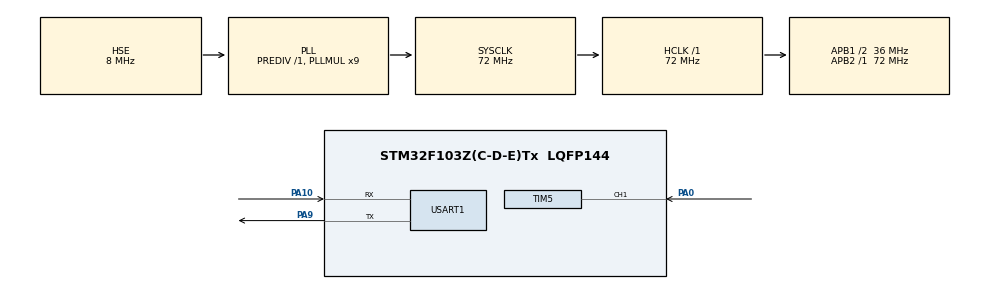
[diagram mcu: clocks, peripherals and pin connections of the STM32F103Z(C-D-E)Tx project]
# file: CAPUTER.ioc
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Mcu.Family=STM32F1
Mcu.Name=STM32F103Z(C-D-E)Tx
Mcu.Package=LQFP144
NVIC.PriorityGroup=NVIC_PRIORITYGROUP_4
NVIC.TIM5_IRQn=true\:0\:0\:false\:false\:true\:true\:true
OSC_IN.Mode=HSE-External-Oscillator
OSC_IN.Signal=RCC_OSC_IN
OSC_OUT.Mode=HSE-External-Oscillator
OSC_OUT.Signal=RCC_OSC_OUT
PA0-WKUP.GPIO_PuPd=GPIO_PULLDOWN
PA0-WKUP.Signal=S_TIM5_CH1
PA10.Mode=Asynchronous
PA10.Signal=USART1_RX
PA9.Mode=Asynchronous
PA9.Signal=USART1_TX
ProjectManager.HeapSize=0x200
ProjectManager.StackSize=0x400
ProjectManager.TargetToolchain=MDK-ARM V5
RCC.AHBFreq_Value=72000000
RCC.APB1CLKDivider=RCC_HCLK_DIV2
RCC.APB1Freq_Value=36000000
RCC.APB1TimFreq_Value=72000000
RCC.APB2Freq_Value=72000000
RCC.APB2TimFreq_Value=72000000
RCC.HCLKFreq_Value=72000000
RCC.PLLMUL=RCC_PLL_MUL9
RCC.PLLSourceVirtual=RCC_PLLSOURCE_HSE
RCC.SYSCLKFreq_VALUE=72000000
RCC.SYSCLKSource=RCC_SYSCLKSOURCE_PLLCLK
RCC.USBFreq_Value=72000000
SH.S_TIM5_CH1.0=TIM5_CH1,Input_Capture1_from_TI1
TIM5.AutoReloadPreload=TIM_AUTORELOAD_PRELOAD_ENABLE
TIM5.Channel-Input_Capture1_from_TI1=TIM_CHANNEL_1
TIM5.Period=0xFFFF
TIM5.Prescaler=72-1
USART1.VirtualMode=VM_ASYNC
VP_SYS_VS_ND.Mode=No_Debug
VP_TIM5_VS_ClockSourceINT.Mode=Internal
board=custom

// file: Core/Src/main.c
/* USER CODE BEGIN Header */
/**
  ******************************************************************************
  * @file           : main.c
  * @brief          : Main program body
  ******************************************************************************
  * @attention
  *
  * <h2><center>&copy; Copyright (c) 2021 STMicroelectronics.
  * All rights reserved.</center></h2>
  *
  * This software component is licensed by ST under BSD 3-Clause license,
  * the "License"; You may not use this file except in compliance with the
  * License. You may obtain a copy of the License at:
  *                        opensource.org/licenses/BSD-3-Clause
  *
  ******************************************************************************
  */
/* USER CODE END Header */
#include "main.h"
#include "tim.h"
#include "usart.h"
#include "gpio.h"

/* USER CODE BEGIN Includes */
#include "stdio.h"
/* USER CODE END Includes */

void SystemClock_Config(void);

int main(void)
{

  /* MCU Configuration--------------------------------------------------------*/

  /* Reset of all peripherals, Initializes the Flash interface and the Systick. */
  HAL_Init();

  /* Configure the system clock */
  SystemClock_Config();

  /* Initialize all configured peripherals */
  MX_GPIO_Init();
  MX_TIM5_Init();
  MX_USART1_UART_Init();

  /* Infinite loop */
  while (1)
  {

    /* USER CODE BEGIN 3 */
      switch (TIM5_CAPTURE_STA)
    {
        case 0:
        {
            printf("# start ----------------------------------------------------\r\n");
            printf("准备捕获上升沿...\r\n");
            TIM5_TIMEOUT_COUNT = 0;
            __HAL_TIM_SET_COUNTER(&htim5, 0);											// 清除定时器2现有计数
            TIM5_CAPTURE_BUF[0] = 0;                                                    // 清除捕获计数
            TIM5_CAPTURE_BUF[1] = 0;
            TIM5_CAPTURE_BUF[2] = 0;
            TIM5_SetCapturePolarity(TIM_INPUTCHANNELPOLARITY_RISING);					// 设置为上升沿触发
            HAL_TIM_Base_Start_IT(&htim5);												// 启动定时器更新中断
            HAL_TIM_IC_Start_IT(&htim5, TIM_CHANNEL_1);									// 启动捕获中断
            TIM5_CAPTURE_STA++;
            break;
        }

        case 4:
        {
            uint32_t high  = TIM5_CAPTURE_BUF[1] - TIM5_CAPTURE_BUF[0];
            uint32_t cycle = TIM5_CAPTURE_BUF[2] - TIM5_CAPTURE_BUF[0];
            float frq = 1.0 / (((float)cycle) / 1000000.0);
            TIM5_CAPTURE_STA = 0;

            printf("\r\n\r\n");
            printf("################################# START #########################################\r\n");
            printf("高电平持续时间：%dms\r\n", high / 1000);
            printf("周期          ：%dms\r\n", cycle / 1000);
            printf("频率          ：%fHz\r\n", frq);
            printf("################################## END ##########################################\r\n\r\n");
            break;
        }

        default:
            break;
    }
  }
  /* USER CODE END 3 */
}

void SystemClock_Config(void)
{
  RCC_OscInitTypeDef RCC_OscInitStruct = {0};
  RCC_ClkInitTypeDef RCC_ClkInitStruct = {0};

  /** Initializes the RCC Oscillators according to the specified parameters
  * in the RCC_OscInitTypeDef structure.
  */
  RCC_OscInitStruct.OscillatorType = RCC_OSCILLATORTYPE_HSE;
  RCC_OscInitStruct.HSEState = RCC_HSE_ON;
  RCC_OscInitStruct.HSEPredivValue = RCC_HSE_PREDIV_DIV1;
  RCC_OscInitStruct.HSIState = RCC_HSI_ON;
  RCC_OscInitStruct.PLL.PLLState = RCC_PLL_ON;
  RCC_OscInitStruct.PLL.PLLSource = RCC_PLLSOURCE_HSE;
  RCC_OscInitStruct.PLL.PLLMUL = RCC_PLL_MUL9;
  if (HAL_RCC_OscConfig(&RCC_OscInitStruct) != HAL_OK)
  {
    Error_Handler();
  }
  /** Initializes the CPU, AHB and APB buses clocks
  */
  RCC_ClkInitStruct.ClockType = RCC_CLOCKTYPE_HCLK|RCC_CLOCKTYPE_SYSCLK
                              |RCC_CLOCKTYPE_PCLK1|RCC_CLOCKTYPE_PCLK2;
  RCC_ClkInitStruct.SYSCLKSource = RCC_SYSCLKSOURCE_PLLCLK;
  RCC_ClkInitStruct.AHBCLKDivider = RCC_SYSCLK_DIV1;
  RCC_ClkInitStruct.APB1CLKDivider = RCC_HCLK_DIV2;
  RCC_ClkInitStruct.APB2CLKDivider = RCC_HCLK_DIV1;

  if (HAL_RCC_ClockConfig(&RCC_ClkInitStruct, FLASH_LATENCY_2) != HAL_OK)
  {
    Error_Handler();
  }
}

void Error_Handler(void)
{
  __disable_irq();
  while (1)
  {
  }
}

/************************ (C) COPYRIGHT STMicroelectronics *****END OF FILE****/
